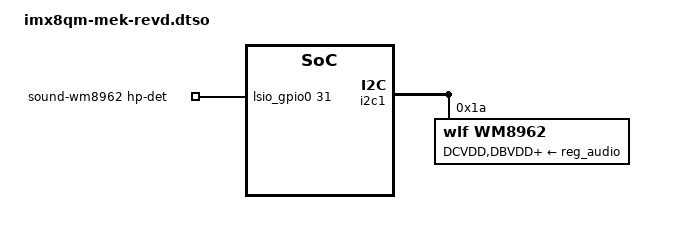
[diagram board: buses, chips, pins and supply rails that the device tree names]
// SPDX-License-Identifier: GPL-2.0+
/*
 * Copyright 2023 NXP
 */

#include <dt-bindings/clock/imx8-clock.h>
#include <dt-bindings/gpio/gpio.h>

/dts-v1/;
/plugin/;

&{/} {

	sound-wm8960 {
		status = "disabled";
	};

	sound-wm8962 {
		compatible = "fsl,imx-audio-wm8962";
		model = "wm8962-audio";
		audio-cpu = <&sai1>;
		audio-codec = <&wm8962>;
		hp-det-gpio = <&lsio_gpio0 31 GPIO_ACTIVE_HIGH>;
		audio-routing =
			"Headphone Jack", "HPOUTL",
			"Headphone Jack", "HPOUTR",
			"Ext Spk", "SPKOUTL",
			"Ext Spk", "SPKOUTR",
			"AMIC", "MICBIAS",
			"IN1R", "AMIC",
			"IN3R", "AMIC";
	};
};

&wm8960 {
	status = "disabled";
};

&i2c1 {
	#address-cells = <1>;
	#size-cells = <0>;

	wm8962: wm8962@1a {
		compatible = "wlf,wm8962";
		reg = <0x1a>;
		clocks = <&mclkout0_lpcg 0>;
		DCVDD-supply = <&reg_audio>;
		DBVDD-supply = <&reg_audio>;
		AVDD-supply = <&reg_audio>;
		CPVDD-supply = <&reg_audio>;
		MICVDD-supply = <&reg_audio>;
		PLLVDD-supply = <&reg_audio>;
		SPKVDD1-supply = <&reg_audio>;
		SPKVDD2-supply = <&reg_audio>;
		gpio-cfg = <
			0x0000 /* 0:Default */
			0x0000 /* 1:Default */
			0x0000 /* 2:FN_DMICCLK */
			0x0000 /* 3:Default */
			0x0000 /* 4:FN_DMICCDAT */
			0x0000 /* 5:Default */
		>;
	};
};
